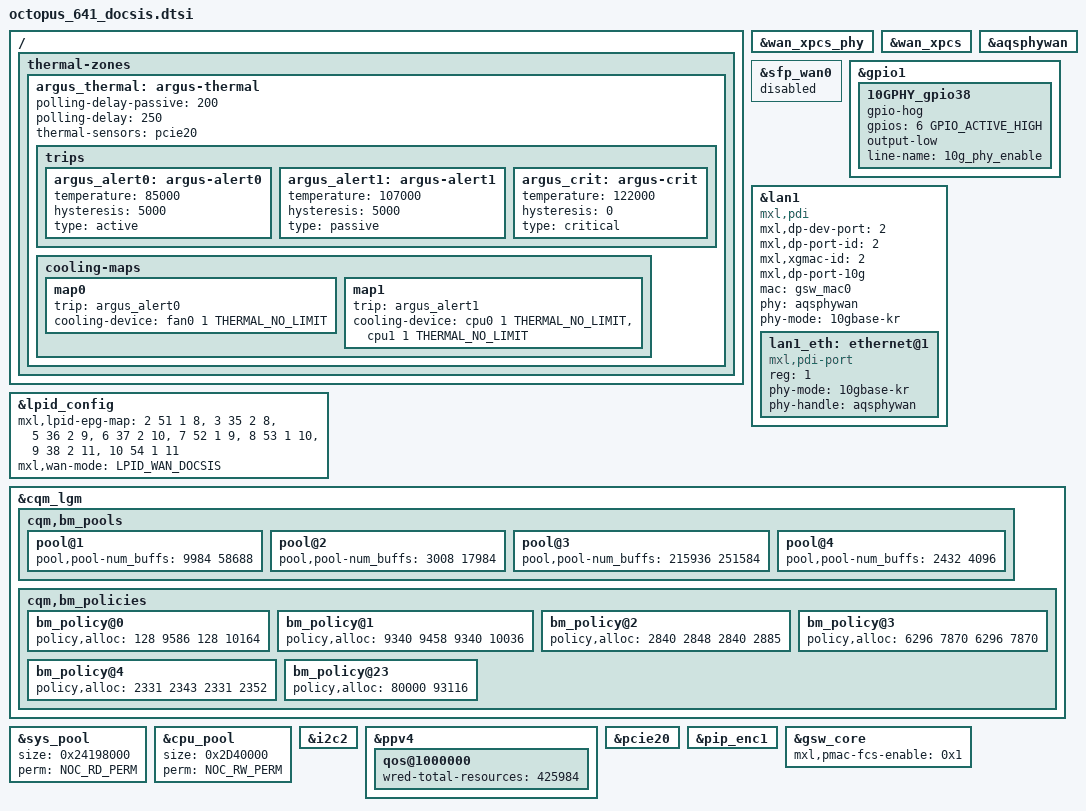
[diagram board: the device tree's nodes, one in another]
// SPDX-License-Identifier: GPL-2.0
/*
 * Copyright (C) 2023 MaxLinear, Inc.
 */

/* 10G WAN PHY as LAN */

/* WAN XPCS PHY */
&wan_xpcs_phy {
	status = "okay";
};

&wan_xpcs {
	status = "okay";
};

&aqsphywan {
	status = "okay";
};

&sfp_wan0 {
	status = "disabled";
};

&gpio1 {
	10GPHY_gpio38 {
		gpio-hog;
		gpios = <6 GPIO_ACTIVE_HIGH>;
		output-low;
		line-name = "10g_phy_enable";
	};
};

&lan1 {
	status = "okay";

	#address-cells = <1>;
	#size-cells = <0>;

	compatible = "mxl,pdi";
	mxl,dp-dev-port = <2>;
	mxl,dp-port-id = <2>;
	mxl,xgmac-id = <2>;
	mxl,dp-port-10g;
	mac = <&gsw_mac0>;
	phy = <&aqsphywan>;
	phy-mode = "10gbase-kr";

	lan1_eth: ethernet@1 {
		compatible = "mxl,pdi-port";
		reg = <1>;
		phy-mode = "10gbase-kr";
		phy-handle = <&aqsphywan>;
	};
};

/* todo: should be moved to /sdk/feed_target_x86/intel_x86/dts/lgp_thermal.dtsi */
/ {
	thermal-zones {
		argus_thermal: argus-thermal {
			polling-delay-passive = <200>; /* milliseconds */
			polling-delay = <250>; /* milliseconds */

			thermal-sensors = <>; /* should define in *_docsis.dts */

			trips {
				argus_alert0: argus-alert0 {
					temperature = <85000>; /* millicelsius */
					hysteresis = <5000>; /* millicelsius */
					type = "active";
				};
				argus_alert1: argus-alert1 {
					temperature = <107000>; /* millicelsius */
					hysteresis = <5000>; /* millicelsius */
					type = "passive";
				};
				argus_crit: argus-crit {
					temperature = <122000>;
					hysteresis = <0>;
					type = "critical";
				};
			};

			cooling-maps {
				map0 {
					trip = <&argus_alert0>;
					cooling-device = <&fan0 1 THERMAL_NO_LIMIT>;
				};
				map1 {
					trip = <&argus_alert1>;
					cooling-device = <&cpu0 1 THERMAL_NO_LIMIT>,
							 <&cpu1 1 THERMAL_NO_LIMIT>;
				};
			};
		};
	};
};

&lpid_config {
	mxl,lpid-epg-map = <2 51 1 8>,
				<3 35 2 8>,
				<5 36 2 9>,
				<6 37 2 10>,
				<7 52 1 9>,
				<8 53 1 10>,
				<9 38 2 11>,
				<10 54 1 11>;
};

&cqm_lgm {
	cqm,bm_pools {
		pool@1 {
			pool,pool-num_buffs = <9984 58688>;
		};
		pool@2 {
			pool,pool-num_buffs = <3008 17984>;
		};
		pool@3 {
			pool,pool-num_buffs = <215936 251584>;
		};
		pool@4 {
			pool,pool-num_buffs = <2432 4096>;
		};
	};
	cqm,bm_policies {
		/delete-node/ bm_policy@12;
		/delete-node/ bm_policy@13;
		/delete-node/ bm_policy@14;
		/delete-node/ bm_policy@15;
		/delete-node/ bm_policy@16;

		bm_policy@0 {
			policy,alloc = <128 9586 128 10164>;
		};
		bm_policy@1 {
			policy,alloc = <9340 9458 9340 10036>;
		};
		bm_policy@2 {
			policy,alloc = <2840 2848 2840 2885>;
		};
		bm_policy@3 {
			policy,alloc = <6296 7870 6296 7870>;
		};
		bm_policy@4 {
			policy,alloc = <2331 2343 2331 2352>;
		};
		bm_policy@23 {
			policy,alloc = <80000 93116>;
		};
	};
};

&sys_pool {
	size = <0x24198000>;
	perm = <NOC_RD_PERM>;
};

&cpu_pool {
	size = <0x2D40000>;
	perm = <NOC_RW_PERM>;
};

&i2c2 {
	status = "okay";
};

&lpid_config {
	mxl,wan-mode = <LPID_WAN_DOCSIS>;
};

&ppv4 {
	qos@1000000 {
		wred-total-resources = <425984>;
	};
};

&pcie20 {
	#thermal-sensor-cells = <0>;
};

&argus_thermal {
	thermal-sensors = <&pcie20>;
};

&pip_enc1 {
	status = "okay";
};

&gsw_core {
	mxl,pmac-fcs-enable = <0x1>; /* set bit 0, i.e. set FCSEN for PMAC0 */
};
